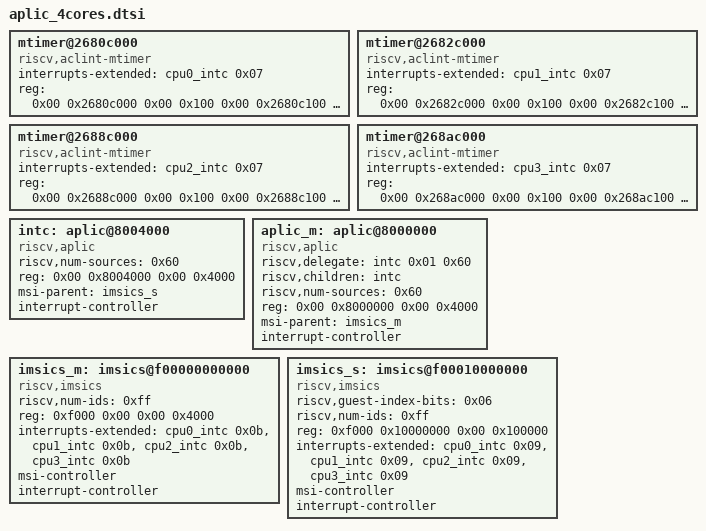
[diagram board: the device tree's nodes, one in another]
		mtimer@2680c000 {
			interrupts-extended = <&cpu0_intc 0x07>;
			reg = <0x00 0x2680c000 0x00 0x100 0x00 0x2680c100 0x00 0xf00>;
			compatible = "riscv,aclint-mtimer";
		};

		mtimer@2682c000 {
			interrupts-extended = <&cpu1_intc 0x07>;
			reg = <0x00 0x2682c000 0x00 0x100 0x00 0x2682c100 0x00 0xf00>;
			compatible = "riscv,aclint-mtimer";
		};

		mtimer@2688c000 {
			interrupts-extended = <&cpu2_intc 0x07>;
			reg = <0x00 0x2688c000 0x00 0x100 0x00 0x2688c100 0x00 0xf00>;
			compatible = "riscv,aclint-mtimer";
		};

		mtimer@268ac000 {
			interrupts-extended = <&cpu3_intc 0x07>;
			reg = <0x00 0x268ac000 0x00 0x100 0x00 0x268ac100 0x00 0xf00>;
			compatible = "riscv,aclint-mtimer";
		};

		intc: aplic@8004000 {
			riscv,num-sources = <0x60>;
			reg = <0x00 0x8004000 0x00 0x4000>;
			msi-parent = <&imsics_s>;
			interrupt-controller;
			#interrupt-cells = <0x02>;
			compatible = "riscv,aplic";
		};

		aplic_m: aplic@8000000 {
			riscv,delegate = <&intc 0x01 0x60>;
			riscv,children = <&intc>;
			riscv,num-sources = <0x60>;
			reg = <0x00 0x8000000 0x00 0x4000>;
			msi-parent = <&imsics_m>;
			interrupt-controller;
			#interrupt-cells = <0x02>;
			compatible = "riscv,aplic";
		};

		imsics_m: imsics@f00000000000 {
			riscv,num-ids = <0xff>;
			reg = <0xf000 0x00 0x00 0x4000>;
			interrupts-extended = <&cpu0_intc 0x0b &cpu1_intc 0x0b &cpu2_intc 0x0b &cpu3_intc 0x0b>;
			msi-controller;
			interrupt-controller;
			#interrupt-cells = <0x00>;
			compatible = "riscv,imsics";
		};

		imsics_s: imsics@f00010000000 {
			riscv,guest-index-bits = <0x06>;
			riscv,num-ids = <0xff>;
			reg = <0xf000 0x10000000 0x00 0x100000>;
			interrupts-extended = <&cpu0_intc 0x09 &cpu1_intc 0x09 &cpu2_intc 0x09 &cpu3_intc 0x09>;
			msi-controller;
			interrupt-controller;
			#interrupt-cells = <0x00>;
			compatible = "riscv,imsics";
		};

